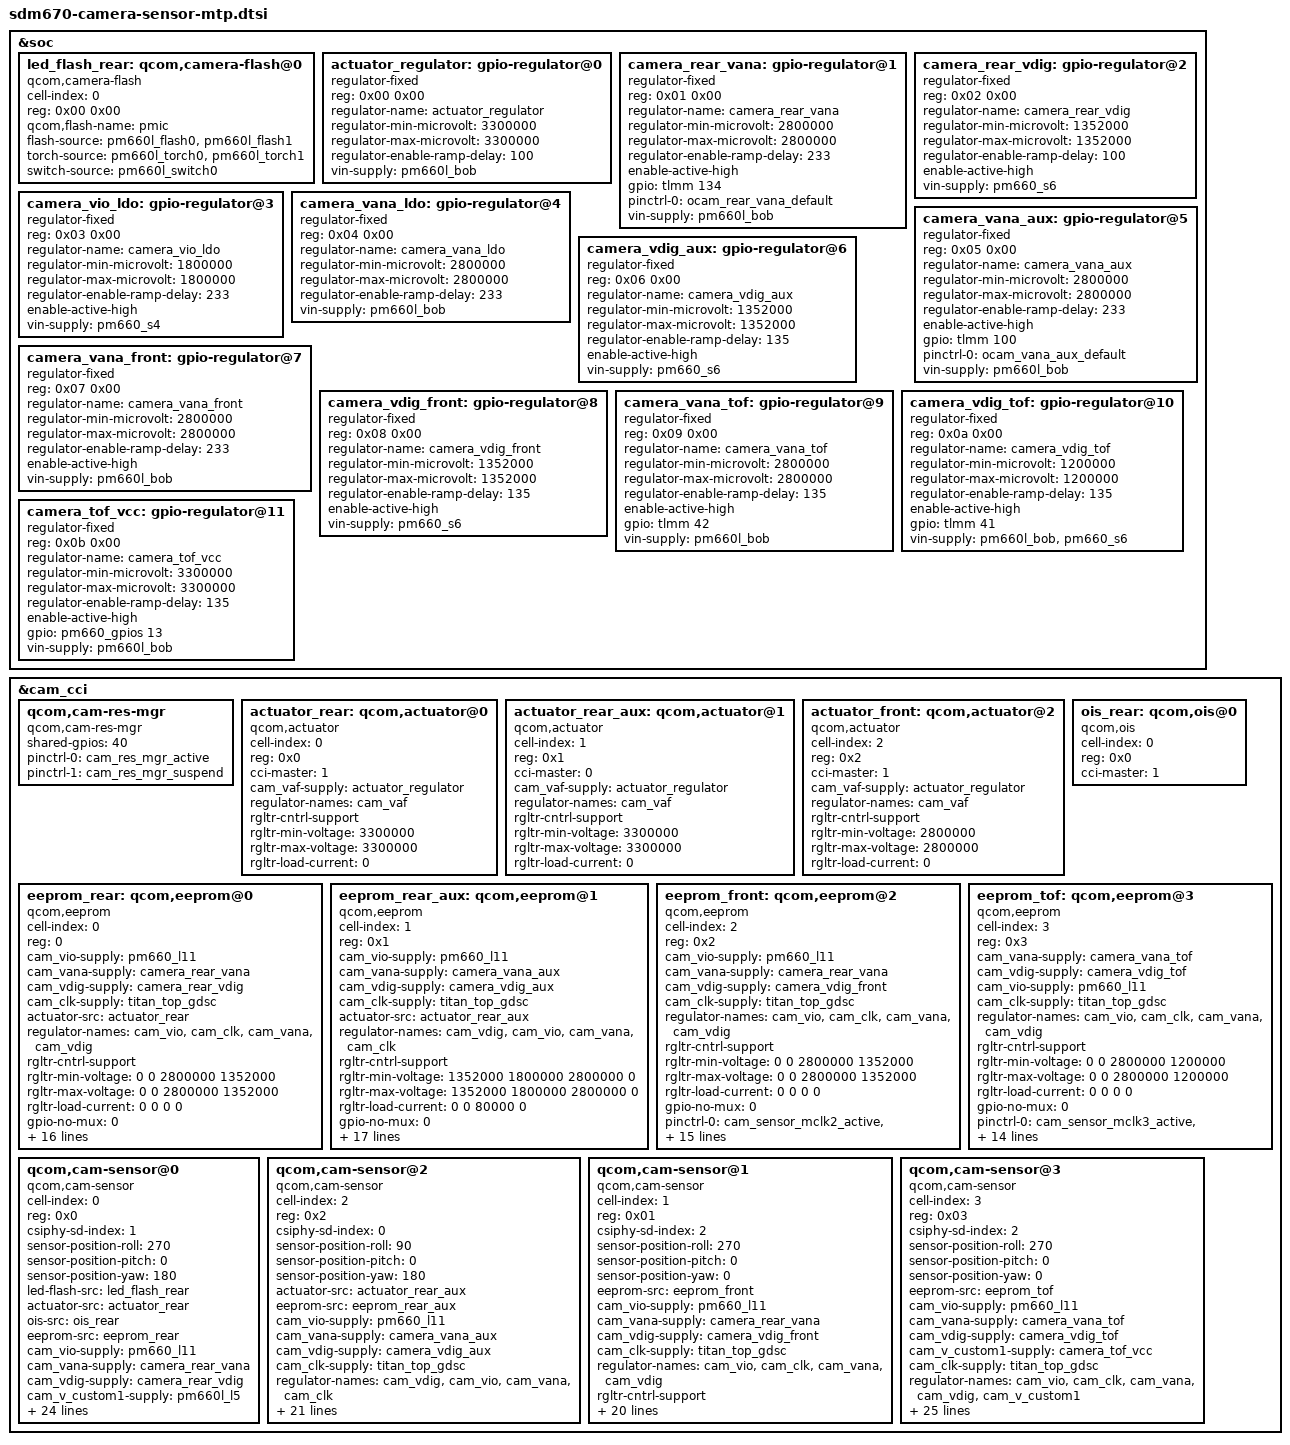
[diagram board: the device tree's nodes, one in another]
/*
 * Copyright (c) 2016-2018, The Linux Foundation. All rights reserved.
 *
 * This program is free software; you can redistribute it and/or modify
 * it under the terms of the GNU General Public License version 2 and
 * only version 2 as published by the Free Software Foundation.
 *
 * This program is distributed in the hope that it will be useful,
 * but WITHOUT ANY WARRANTY; without even the implied warranty of
 * MERCHANTABILITY or FITNESS FOR A PARTICULAR PURPOSE.  See the
 * GNU General Public License for more details.
 */

/*#ifndef VENDOR_EDIT*/
/*Yingpiao.Lin@Camera.Driver, 20180714, modify for oppo camera driver*/
/*
&soc {
	led_flash_rear: qcom,camera-flash@0 {
		cell-index = <0>;
		reg = <0x00 0x00>;
		compatible = "qcom,camera-flash";
		flash-source = <&pm660l_flash0 &pm660l_flash1>;
		torch-source = <&pm660l_torch0 &pm660l_torch1>;
		switch-source = <&pm660l_switch0>;
		status = "ok";
	};

	led_flash_rear_aux: qcom,camera-flash@1 {
		cell-index = <1>;
		reg = <0x01 0x00>;
		compatible = "qcom,camera-flash";
		flash-source = <&pm660l_flash0 &pm660l_flash1>;
		torch-source = <&pm660l_torch0 &pm660l_torch1>;
		switch-source = <&pm660l_switch0>;
		status = "ok";
	};

	led_flash_front: qcom,camera-flash@2 {
		cell-index = <2>;
		reg = <0x02 0x00>;
		compatible = "qcom,camera-flash";
		flash-source = <&pm660l_flash2>;
		torch-source = <&pm660l_torch2>;
		switch-source = <&pm660l_switch1>;
		status = "ok";
	};

	actuator_regulator: gpio-regulator@0 {
		compatible = "regulator-fixed";
		reg = <0x00 0x00>;
		regulator-name = "actuator_regulator";
		regulator-min-microvolt = <2800000>;
		regulator-max-microvolt = <2800000>;
		regulator-enable-ramp-delay = <100>;
		enable-active-high;
		gpio = <&tlmm 27 0>;
	};

	camera_ldo: gpio-regulator@2 {
		compatible = "regulator-fixed";
		reg = <0x02 0x00>;
		regulator-name = "camera_ldo";
		regulator-min-microvolt = <1352000>;
		regulator-max-microvolt = <1352000>;
		regulator-enable-ramp-delay = <233>;
		enable-active-high;
		gpio = <&pm660l_gpios 3 0>;
		pinctrl-names = "default";
		pinctrl-0 = <&camera_dvdd_en_default>;
		vin-supply = <&pm660_s6>;
	};

	camera_rear_ldo: gpio-regulator@1 {
		compatible = "regulator-fixed";
		reg = <0x01 0x00>;
		regulator-name = "camera_rear_ldo";
		regulator-min-microvolt = <1352000>;
		regulator-max-microvolt = <1352000>;
		regulator-enable-ramp-delay = <135>;
		enable-active-high;
		gpio = <&pm660l_gpios 4 0>;
		pinctrl-names = "default";
		pinctrl-0 = <&camera_rear_dvdd_en_default>;
		vin-supply = <&pm660_s6>;
	};

	camera_vio_ldo: gpio-regulator@3 {
		compatible = "regulator-fixed";
		reg = <0x03 0x00>;
		regulator-name = "camera_vio_ldo";
		regulator-min-microvolt = <1800000>;
		regulator-max-microvolt = <1800000>;
		regulator-enable-ramp-delay = <233>;
		enable-active-high;
		gpio = <&tlmm 29 0>;
		pinctrl-names = "default";
		pinctrl-0 = <&cam_sensor_rear_vio>;
		vin-supply = <&pm660_s4>;
	};

	camera_vana_ldo: gpio-regulator@4 {
		compatible = "regulator-fixed";
		reg = <0x04 0x00>;
		regulator-name = "camera_vana_ldo";
		regulator-min-microvolt = <2850000>;
		regulator-max-microvolt = <2850000>;
		regulator-enable-ramp-delay = <233>;
		enable-active-high;
		gpio = <&tlmm 8 0>;
		pinctrl-names = "default";
		pinctrl-0 = <&cam_sensor_rear_vana>;
		vin-supply = <&pm660l_bob>;
	};
};

&cam_cci {
	qcom,cam-res-mgr {
		compatible = "qcom,cam-res-mgr";
		status = "ok";
	};

	actuator_rear: qcom,actuator@0 {
		cell-index = <0>;
		reg = <0x0>;
		compatible = "qcom,actuator";
		cci-master = <0>;
		cam_vaf-supply = <&actuator_regulator>;
		regulator-names = "cam_vaf";
		rgltr-cntrl-support;
		rgltr-min-voltage = <2800000>;
		rgltr-max-voltage = <2800000>;
		rgltr-load-current = <0>;
	};

	actuator_rear_aux: qcom,actuator@1 {
		cell-index = <1>;
		reg = <0x1>;
		compatible = "qcom,actuator";
		cci-master = <1>;
		cam_vaf-supply = <&actuator_regulator>;
		regulator-names = "cam_vaf";
		rgltr-cntrl-support;
		rgltr-min-voltage = <2800000>;
		rgltr-max-voltage = <2800000>;
		rgltr-load-current = <0>;
	};

	actuator_front: qcom,actuator@2 {
		cell-index = <2>;
		reg = <0x2>;
		compatible = "qcom,actuator";
		cci-master = <1>;
		cam_vaf-supply = <&actuator_regulator>;
		regulator-names = "cam_vaf";
		rgltr-cntrl-support;
		rgltr-min-voltage = <2800000>;
		rgltr-max-voltage = <2800000>;
		rgltr-load-current = <0>;
	};

	ois_rear: qcom,ois@0 {
		cell-index = <0>;
		reg = <0x0>;
		compatible = "qcom,ois";
		cci-master = <0>;
		cam_vaf-supply = <&actuator_regulator>;
		regulator-names = "cam_vaf";
		rgltr-cntrl-support;
		rgltr-min-voltage = <2800000>;
		rgltr-max-voltage = <2800000>;
		rgltr-load-current = <0>;
		status = "disabled";
	};

	eeprom_rear: qcom,eeprom@0 {
		cell-index = <0>;
		reg = <0>;
		compatible = "qcom,eeprom";
		cam_vio-supply = <&camera_vio_ldo>;
		cam_vana-supply = <&camera_vana_ldo>;
		cam_vdig-supply = <&camera_rear_ldo>;
		cam_clk-supply = <&titan_top_gdsc>;
		cam_vaf-supply = <&actuator_regulator>;
		regulator-names = "cam_vio", "cam_vana", "cam_vdig",
			"cam_clk", "cam_vaf";
		rgltr-cntrl-support;
		rgltr-min-voltage = <1800000 2850000 1352000 0 2800000>;
		rgltr-max-voltage = <1800000 2850000 1352000 0 2800000>;
		rgltr-load-current = <0 80000 105000 0 0>;
		gpio-no-mux = <0>;
		pinctrl-names = "cam_default", "cam_suspend";
		pinctrl-0 = <&cam_sensor_mclk0_active
				&cam_sensor_rear_active>;
		pinctrl-1 = <&cam_sensor_mclk0_suspend
				&cam_sensor_rear_suspend>;
		gpios = <&tlmm 13 0>,
			<&tlmm 30 0>;
		gpio-reset = <1>;
		gpio-req-tbl-num = <0 1>;
		gpio-req-tbl-flags = <1 0>;
		gpio-req-tbl-label = "CAMIF_MCLK0",
					"CAM_RESET0";
		sensor-mode = <0>;
		cci-master = <0>;
		status = "ok";
		clocks = <&clock_camcc CAM_CC_MCLK0_CLK>;
		clock-names = "cam_clk";
		clock-cntl-level = "turbo";
		clock-rates = <24000000>;
	};

	eeprom_rear_aux: qcom,eeprom@1 {
		cell-index = <1>;
		reg = <0x1>;
		compatible = "qcom,eeprom";
		cam_vio-supply = <&camera_vio_ldo>;
		cam_vana-supply = <&camera_vana_ldo>;
		cam_vdig-supply = <&camera_ldo>;
		cam_clk-supply = <&titan_top_gdsc>;
		cam_vaf-supply = <&actuator_regulator>;
		regulator-names = "cam_vdig", "cam_vio", "cam_vana",
			"cam_clk", "cam_vaf";
		rgltr-cntrl-support;
		rgltr-min-voltage = <1352000 1800000 2850000 0 2800000>;
		rgltr-max-voltage = <1352000 1800000 2850000 0 2800000>;
		rgltr-load-current = <105000 0 80000 0 0>;
		gpio-no-mux = <0>;
		pinctrl-names = "cam_default", "cam_suspend";
		pinctrl-0 = <&cam_sensor_mclk1_active
				&cam_sensor_rear2_active>;
		pinctrl-1 = <&cam_sensor_mclk1_suspend
				&cam_sensor_rear2_suspend>;
		gpios = <&tlmm 14 0>,
			<&tlmm 28 0>;
		gpio-reset = <1>;
		gpio-req-tbl-num = <0 1>;
		gpio-req-tbl-flags = <1 0>;
		gpio-req-tbl-label = "CAMIF_MCLK1",
					"CAM_RESET1";
		sensor-position = <0>;
		sensor-mode = <0>;
		cci-master = <1>;
		status = "ok";
		clock-names = "cam_clk";
		clock-cntl-level = "turbo";
		clock-rates = <24000000>;
	};

	eeprom_front: qcom,eeprom@2 {
		cell-index = <2>;
		reg = <0x2>;
		compatible = "qcom,eeprom";
		cam_vio-supply = <&camera_vio_ldo>;
		cam_vana-supply = <&camera_vana_ldo>;
		cam_vdig-supply = <&camera_ldo>;
		cam_clk-supply = <&titan_top_gdsc>;
		cam_vaf-supply = <&actuator_regulator>;
		regulator-names = "cam_vio", "cam_vana", "cam_vdig",
			"cam_clk", "cam_vaf";
		rgltr-cntrl-support;
		rgltr-min-voltage = <1800000 2850000 1352000 0 2800000>;
		rgltr-max-voltage = <1800000 2850000 1352000 0 2800000>;
		rgltr-load-current = <0 80000 105000 0 0>;
		gpio-no-mux = <0>;
		pinctrl-names = "cam_default", "cam_suspend";
		pinctrl-0 = <&cam_sensor_mclk2_active
				 &cam_sensor_front_active>;
		pinctrl-1 = <&cam_sensor_mclk2_suspend
				 &cam_sensor_front_suspend>;
		gpios = <&tlmm 15 0>,
			<&tlmm 9 0>;
		gpio-reset = <1>;
		gpio-req-tbl-num = <0 1>;
		gpio-req-tbl-flags = <1 0>;
		gpio-req-tbl-label = "CAMIF_MCLK2",
					"CAM_RESET2";
		sensor-mode = <0>;
		cci-master = <1>;
		status = "ok";
		clocks = <&clock_camcc CAM_CC_MCLK2_CLK>;
		clock-names = "cam_clk";
		clock-cntl-level = "turbo";
		clock-rates = <24000000>;
	};

	qcom,cam-sensor@0 {
		cell-index = <0>;
		compatible = "qcom,cam-sensor";
		reg = <0x0>;
		csiphy-sd-index = <0>;
		sensor-position-roll = <270>;
		sensor-position-pitch = <0>;
		sensor-position-yaw = <180>;
		led-flash-src = <&led_flash_rear>;
		actuator-src = <&actuator_rear>;
		ois-src = <&ois_rear>;
		eeprom-src = <&eeprom_rear>;
		cam_vio-supply = <&camera_vio_ldo>;
		cam_vana-supply = <&camera_vana_ldo>;
		cam_vdig-supply = <&camera_rear_ldo>;
		cam_clk-supply = <&titan_top_gdsc>;
		regulator-names = "cam_vio", "cam_vana", "cam_vdig",
			"cam_clk";
		rgltr-cntrl-support;
		rgltr-min-voltage = <1800000 2850000 1352000 0>;
		rgltr-max-voltage = <1800000 2850000 1352000 0>;
		rgltr-load-current = <0 80000 105000 0>;
		gpio-no-mux = <0>;
		pinctrl-names = "cam_default", "cam_suspend";
		pinctrl-0 = <&cam_sensor_mclk0_active
				&cam_sensor_rear_active>;
		pinctrl-1 = <&cam_sensor_mclk0_suspend
				&cam_sensor_rear_suspend>;
		gpios = <&tlmm 13 0>,
			<&tlmm 30 0>;
		gpio-reset = <1>;
		gpio-req-tbl-num = <0 1>;
		gpio-req-tbl-flags = <1 0>;
		gpio-req-tbl-label = "CAMIF_MCLK0",
					"CAM_RESET0";
		sensor-mode = <0>;
		cci-master = <0>;
		status = "ok";
		clocks = <&clock_camcc CAM_CC_MCLK0_CLK>;
		clock-names = "cam_clk";
		clock-cntl-level = "turbo";
		clock-rates = <24000000>;
	};

	qcom,cam-sensor@1 {
		cell-index = <1>;
		compatible = "qcom,cam-sensor";
		reg = <0x1>;
		csiphy-sd-index = <1>;
		sensor-position-roll = <270>;
		sensor-position-pitch = <0>;
		sensor-position-yaw = <180>;
		led-flash-src = <&led_flash_rear_aux>;
		actuator-src = <&actuator_rear_aux>;
		eeprom-src = <&eeprom_rear_aux>;
		cam_vio-supply = <&camera_vio_ldo>;
		cam_vana-supply = <&camera_vana_ldo>;
		cam_vdig-supply = <&camera_ldo>;
		cam_clk-supply = <&titan_top_gdsc>;
		regulator-names = "cam_vdig", "cam_vio", "cam_vana",
			"cam_clk";
		rgltr-cntrl-support;
		rgltr-min-voltage = <1352000 1800000 2850000 0>;
		rgltr-max-voltage = <1352000 1800000 2850000 0>;
		rgltr-load-current = <105000 0 80000 0>;
		gpio-no-mux = <0>;
		pinctrl-names = "cam_default", "cam_suspend";
		pinctrl-0 = <&cam_sensor_mclk1_active
				&cam_sensor_rear2_active>;
		pinctrl-1 = <&cam_sensor_mclk1_suspend
				&cam_sensor_rear2_suspend>;
		gpios = <&tlmm 14 0>,
			<&tlmm 28 0>;
		gpio-reset = <1>;
		gpio-req-tbl-num = <0 1>;
		gpio-req-tbl-flags = <1 0>;
		gpio-req-tbl-label = "CAMIF_MCLK1",
					"CAM_RESET1";
		sensor-mode = <0>;
		cci-master = <1>;
		status = "ok";
		clocks = <&clock_camcc CAM_CC_MCLK1_CLK>;
		clock-names = "cam_clk";
		clock-cntl-level = "turbo";
		clock-rates = <24000000>;
	};

	qcom,cam-sensor@2 {
		cell-index = <2>;
		compatible = "qcom,cam-sensor";
		reg = <0x02>;
		csiphy-sd-index = <2>;
		sensor-position-roll = <270>;
		sensor-position-pitch = <0>;
		sensor-position-yaw = <0>;
		eeprom-src = <&eeprom_front>;
		actuator-src = <&actuator_front>;
		led-flash-src = <&led_flash_front>;
		cam_vio-supply = <&camera_vio_ldo>;
		cam_vana-supply = <&camera_vana_ldo>;
		cam_vdig-supply = <&camera_ldo>;
		cam_clk-supply = <&titan_top_gdsc>;
		regulator-names = "cam_vio", "cam_vana", "cam_vdig",
			"cam_clk";
		rgltr-cntrl-support;
		rgltr-min-voltage = <1800000 2850000 1352000 0>;
		rgltr-max-voltage = <1800000 2850000 1352000 0>;
		rgltr-load-current = <0 80000 105000 0>;
		gpio-no-mux = <0>;
		pinctrl-names = "cam_default", "cam_suspend";
		pinctrl-0 = <&cam_sensor_mclk2_active
				 &cam_sensor_front_active>;
		pinctrl-1 = <&cam_sensor_mclk2_suspend
				 &cam_sensor_front_suspend>;
		gpios = <&tlmm 15 0>,
			<&tlmm 9 0>;
		gpio-reset = <1>;
		gpio-req-tbl-num = <0 1>;
		gpio-req-tbl-flags = <1 0>;
		gpio-req-tbl-label = "CAMIF_MCLK2",
					"CAM_RESET2";
		sensor-mode = <0>;
		cci-master = <1>;
		status = "ok";
		clocks = <&clock_camcc CAM_CC_MCLK2_CLK>;
		clock-names = "cam_clk";
		clock-cntl-level = "turbo";
		clock-rates = <24000000>;
	};
};
*/
/*#else*/

&soc {
	led_flash_rear: qcom,camera-flash@0 {
		cell-index = <0>;
		reg = <0x00 0x00>;
		compatible = "qcom,camera-flash";
		qcom,flash-name = "pmic";
		flash-source = <&pm660l_flash0 &pm660l_flash1>;
		torch-source = <&pm660l_torch0 &pm660l_torch1>;
		switch-source = <&pm660l_switch0>;
		status = "ok";
	};

	/*led_flash_rear_aux: qcom,camera-flash@1 {
		cell-index = <1>;
		reg = <0x01 0x00>;
		compatible = "qcom,camera-flash";
		flash-source = <&pm660l_flash0 &pm660l_flash1>;
		torch-source = <&pm660l_torch0 &pm660l_torch1>;
		switch-source = <&pm660l_switch0>;
		status = "ok";
	};

	led_flash_front: qcom,camera-flash@2 {
		cell-index = <2>;
		reg = <0x02 0x00>;
		compatible = "qcom,camera-flash";
		flash-source = <&pm660l_flash2>;
		torch-source = <&pm660l_torch2>;
		switch-source = <&pm660l_switch1>;
		status = "ok";
	};*/

	actuator_regulator: gpio-regulator@0 {
		compatible = "regulator-fixed";
		reg = <0x00 0x00>;
		regulator-name = "actuator_regulator";
		regulator-min-microvolt = <3300000>;
		regulator-max-microvolt = <3300000>;
		regulator-enable-ramp-delay = <100>;
		vin-supply = <&pm660l_bob>;
	};

	camera_rear_vana: gpio-regulator@1 {
		compatible = "regulator-fixed";
		reg = <0x01 0x00>;
		regulator-name = "camera_rear_vana";
		regulator-min-microvolt = <2800000>;
		regulator-max-microvolt = <2800000>;
		regulator-enable-ramp-delay = <233>;
		enable-active-high;
		gpio = <&tlmm 134 0>;
		pinctrl-names = "default";
		pinctrl-0 = <&ocam_rear_vana_default>;
		vin-supply = <&pm660l_bob>;
	};

	camera_rear_vdig: gpio-regulator@2 {
		compatible = "regulator-fixed";
		reg = <0x02 0x00>;
		regulator-name = "camera_rear_vdig";
		regulator-min-microvolt = <1352000>;
		regulator-max-microvolt = <1352000>;
		regulator-enable-ramp-delay = <100>;
		enable-active-high;
		vin-supply = <&pm660_s6>;
	};

	camera_vio_ldo: gpio-regulator@3 {
		compatible = "regulator-fixed";
		reg = <0x03 0x00>;
		regulator-name = "camera_vio_ldo";
		regulator-min-microvolt = <1800000>;
		regulator-max-microvolt = <1800000>;
		regulator-enable-ramp-delay = <233>;
		enable-active-high;
		vin-supply = <&pm660_s4>;
	};

	camera_vana_ldo: gpio-regulator@4 {
		compatible = "regulator-fixed";
		reg = <0x04 0x00>;
		regulator-name = "camera_vana_ldo";
		regulator-min-microvolt = <2800000>;
		regulator-max-microvolt = <2800000>;
		regulator-enable-ramp-delay = <233>;
		vin-supply = <&pm660l_bob>;
	};

	camera_vana_aux: gpio-regulator@5 {
		compatible = "regulator-fixed";
		reg = <0x05 0x00>;
		regulator-name = "camera_vana_aux";
		regulator-min-microvolt = <2800000>;
		regulator-max-microvolt = <2800000>;
		regulator-enable-ramp-delay = <233>;
		enable-active-high;
		gpio = <&tlmm 100 0>;
		pinctrl-names = "default";
		pinctrl-0 = <&ocam_vana_aux_default>;
		vin-supply = <&pm660l_bob>;
	};

	camera_vdig_aux: gpio-regulator@6 {
		compatible = "regulator-fixed";
		reg = <0x06 0x00>;
		regulator-name = "camera_vdig_aux";
		regulator-min-microvolt = <1352000>;
		regulator-max-microvolt = <1352000>;
		regulator-enable-ramp-delay = <135>;
		enable-active-high;
		vin-supply = <&pm660_s6>;
	};

	camera_vana_front: gpio-regulator@7 {
		compatible = "regulator-fixed";
		reg = <0x07 0x00>;
		regulator-name = "camera_vana_front";
		regulator-min-microvolt = <2800000>;
		regulator-max-microvolt = <2800000>;
		regulator-enable-ramp-delay = <233>;
		enable-active-high;
		vin-supply = <&pm660l_bob>;
	};

	camera_vdig_front: gpio-regulator@8 {
		compatible = "regulator-fixed";
		reg = <0x08 0x00>;
		regulator-name = "camera_vdig_front";
		regulator-min-microvolt = <1352000>;
		regulator-max-microvolt = <1352000>;
		regulator-enable-ramp-delay = <135>;
		enable-active-high;
		vin-supply = <&pm660_s6>;
	};

	camera_vana_tof: gpio-regulator@9 {
		compatible = "regulator-fixed";
		reg = <0x09 0x00>;
		regulator-name = "camera_vana_tof";
		regulator-min-microvolt = <2800000>;
		regulator-max-microvolt = <2800000>;
		regulator-enable-ramp-delay = <135>;
		enable-active-high;
		gpio = <&tlmm 42 0>;
		vin-supply = <&pm660l_bob>;
	};

	camera_vdig_tof: gpio-regulator@10 {
		compatible = "regulator-fixed";
		reg = <0x0a 0x00>;
		regulator-name = "camera_vdig_tof";
		regulator-min-microvolt = <1200000>;
		regulator-max-microvolt = <1200000>;
		regulator-enable-ramp-delay = <135>;
		enable-active-high;
		gpio = <&tlmm 41 0>;
		vin-supply = <&pm660l_bob &pm660_s6>;
	};

	camera_tof_vcc: gpio-regulator@11 {
		compatible = "regulator-fixed";
		reg = <0x0b 0x00>;
		regulator-name = "camera_tof_vcc";
		regulator-min-microvolt = <3300000>;
		regulator-max-microvolt = <3300000>;
		regulator-enable-ramp-delay = <135>;
		enable-active-high;
		gpio = <&pm660_gpios 13 0>;
		vin-supply = <&pm660l_bob>;
	};
};

&cam_cci {
	qcom,cam-res-mgr {
		compatible = "qcom,cam-res-mgr";
		status = "ok";
		shared-gpios = <40>;
		pinctrl-names = "cam_res_mgr_default", "cam_res_mgr_suspend";
		pinctrl-0 = <&cam_res_mgr_active>;
		pinctrl-1 = <&cam_res_mgr_suspend>;
	};

	actuator_rear: qcom,actuator@0 {
		cell-index = <0>;
		reg = <0x0>;
		compatible = "qcom,actuator";
		cci-master = <1>;
		cam_vaf-supply = <&actuator_regulator>;
		regulator-names = "cam_vaf";
		rgltr-cntrl-support;
		rgltr-min-voltage = <3300000>;
		rgltr-max-voltage = <3300000>;
		rgltr-load-current = <0>;
	};

	actuator_rear_aux: qcom,actuator@1 {
		cell-index = <1>;
		reg = <0x1>;
		compatible = "qcom,actuator";
		cci-master = <0>;
		cam_vaf-supply = <&actuator_regulator>;
		regulator-names = "cam_vaf";
		rgltr-cntrl-support;
		rgltr-min-voltage = <3300000>;
		rgltr-max-voltage = <3300000>;
		rgltr-load-current = <0>;
	};

	actuator_front: qcom,actuator@2 {
		cell-index = <2>;
		reg = <0x2>;
		compatible = "qcom,actuator";
		cci-master = <1>;
		cam_vaf-supply = <&actuator_regulator>;
		regulator-names = "cam_vaf";
		rgltr-cntrl-support;
		rgltr-min-voltage = <2800000>;
		rgltr-max-voltage = <2800000>;
		rgltr-load-current = <0>;
	};

	ois_rear: qcom,ois@0 {
		cell-index = <0>;
		reg = <0x0>;
		compatible = "qcom,ois";
		cci-master = <1>;
		status = "ok";
	};

	eeprom_rear: qcom,eeprom@0 {
		cell-index = <0>;
		reg = <0>;
		compatible = "qcom,eeprom";
		cam_vio-supply = <&pm660_l11>;
		cam_vana-supply = <&camera_rear_vana>;
		cam_vdig-supply = <&camera_rear_vdig>;
		cam_clk-supply = <&titan_top_gdsc>;
		actuator-src = <&actuator_rear>;
		regulator-names = "cam_vio", "cam_clk", "cam_vana", "cam_vdig";
		rgltr-cntrl-support;
		rgltr-min-voltage = <0 0 2800000 1352000>;
		rgltr-max-voltage = <0 0 2800000 1352000>;
		rgltr-load-current = <0 0 0 0>;
		gpio-no-mux = <0>;
		pinctrl-names = "cam_default", "cam_suspend";
		pinctrl-0 = <&cam_sensor_mclk1_active
				&ocam_sensor_rear_active>;
		pinctrl-1 = <&cam_sensor_mclk1_suspend
				&ocam_sensor_rear_suspend>;
		gpios = <&tlmm 14 0>,
			<&tlmm 28 0>,
			<&tlmm 40 0>;
		gpio-reset = <1>;
		gpio-standby = <2>;
		gpio-req-tbl-num = <0 1 2>;
		gpio-req-tbl-flags = <1 0 0>;
		gpio-req-tbl-label = "CAMIF_MCLK0",
					"CAM_RESET0", "CAM_STBY0";
		sensor-mode = <0>;
		cci-master = <1>;
		status = "ok";
		clocks = <&clock_camcc CAM_CC_MCLK1_CLK>;
		clock-names = "cam_clk";
		clock-cntl-level = "turbo";
		clock-rates = <24000000>;
	};

	eeprom_rear_aux: qcom,eeprom@1 {
		cell-index = <1>;
		reg = <0x1>;
		compatible = "qcom,eeprom";
		cam_vio-supply = <&pm660_l11>;
		cam_vana-supply = <&camera_vana_aux>;
		cam_vdig-supply = <&camera_vdig_aux>;
		cam_clk-supply = <&titan_top_gdsc>;
		actuator-src = <&actuator_rear_aux>;
		regulator-names = "cam_vdig", "cam_vio", "cam_vana",
			"cam_clk";
		rgltr-cntrl-support;
		rgltr-min-voltage = <1352000 1800000 2800000 0>;
		rgltr-max-voltage = <1352000 1800000 2800000 0>;
		rgltr-load-current = <0 0 80000 0>;
		gpio-no-mux = <0>;
		pinctrl-names = "cam_default", "cam_suspend";
		pinctrl-0 = <&cam_sensor_mclk0_active
				&ocam_sensor_rear2_active>;
		pinctrl-1 = <&cam_sensor_mclk0_suspend
				&ocam_sensor_rear2_suspend>;
		gpios = <&tlmm 13 0>,
			<&tlmm 30 0>, <&tlmm 40 0>;
		gpio-reset = <1>;
		gpio-standby = <2>;
		gpio-req-tbl-num = <0 1 2>;
		gpio-req-tbl-flags = <1 0 0>;
		gpio-req-tbl-label = "CAMIF_MCLK1",
					"CAM_RESET1","CAM_STBY1";
		sensor-position = <0>;
		sensor-mode = <0>;
		cci-master = <0>;
		status = "ok";
		clocks = <&clock_camcc CAM_CC_MCLK0_CLK>;
		clock-names = "cam_clk";
		clock-cntl-level = "turbo";
		clock-rates = <24000000>;
	};

	eeprom_front: qcom,eeprom@2 {
		cell-index = <2>;
		reg = <0x2>;
		compatible = "qcom,eeprom";
		cam_vio-supply = <&pm660_l11>;
		cam_vana-supply = <&camera_rear_vana>;
		cam_vdig-supply = <&camera_vdig_front>;
		cam_clk-supply = <&titan_top_gdsc>;
		regulator-names = "cam_vio", "cam_clk", "cam_vana", "cam_vdig";
		rgltr-cntrl-support;
		rgltr-min-voltage = <0 0 2800000 1352000>;
		rgltr-max-voltage = <0 0 2800000 1352000>;
		rgltr-load-current = <0 0 0 0>;
		gpio-no-mux = <0>;
		pinctrl-names = "cam_default", "cam_suspend";
		pinctrl-0 = <&cam_sensor_mclk2_active
				&ocam_sensor_front_active>;
		pinctrl-1 = <&cam_sensor_mclk2_suspend
				&ocam_sensor_front_suspend>;
		gpios = <&tlmm 15 0>,
			<&tlmm 9 0>,
			<&tlmm 23 0>;
		gpio-reset = <1>;
		gpio-standby = <2>;
		gpio-req-tbl-num = <0 1 2>;
		gpio-req-tbl-flags = <1 0 0>;
		gpio-req-tbl-label = "CAMIF_MCLK2",
					"CAM_RESET2", "CAM_STBY";
		sensor-mode = <1>;
		cci-master = <1>;
		status = "ok";
		clocks = <&clock_camcc CAM_CC_MCLK2_CLK>;
		clock-names = "cam_clk";
		clock-cntl-level = "turbo";
		clock-rates = <24000000>;
	};

	eeprom_tof: qcom,eeprom@3 {
		cell-index = <3>;
		reg = <0x3>;
		compatible = "qcom,eeprom";
		cam_vana-supply = <&camera_vana_tof>;
		cam_vdig-supply = <&camera_vdig_tof>;
		cam_vio-supply = <&pm660_l11>;
		cam_clk-supply = <&titan_top_gdsc>;
		regulator-names = "cam_vio", "cam_clk", "cam_vana", "cam_vdig";
		rgltr-cntrl-support;
		rgltr-min-voltage = <0 0 2800000 1200000>;
		rgltr-max-voltage = <0 0 2800000 1200000>;
		rgltr-load-current = <0 0 0 0>;
		gpio-no-mux = <0>;
		pinctrl-names = "cam_default", "cam_suspend";
		pinctrl-0 = <&cam_sensor_mclk3_active
				 &cam_sensor_tof_active>;
		pinctrl-1 = <&cam_sensor_mclk3_suspend
				 &cam_sensor_tof_suspend>;
		gpios = <&tlmm 16 0>,
			<&tlmm 8 0>;
		gpio-reset = <1>;
		gpio-req-tbl-num = <0 1>;
		gpio-req-tbl-flags = <1 0>;
		gpio-req-tbl-label = "CAMIF_MCLK3",
					"CAM_RESET3";
		sensor-position = <1>;
		sensor-mode = <0>;
		cci-master = <0>;
		status = "ok";
		clocks = <&clock_camcc CAM_CC_MCLK3_CLK>;
		clock-names = "cam_clk";
		clock-cntl-level = "turbo";
		clock-rates = <24000000>;
	};

	qcom,cam-sensor@0 {
		cell-index = <0>;
		compatible = "qcom,cam-sensor";
		reg = <0x0>;
		csiphy-sd-index = <1>;
		sensor-position-roll = <270>;
		sensor-position-pitch = <0>;
		sensor-position-yaw = <180>;
		led-flash-src = <&led_flash_rear>;
		actuator-src = <&actuator_rear>;
		ois-src = <&ois_rear>;
		eeprom-src = <&eeprom_rear>;
		cam_vio-supply = <&pm660_l11>;
		cam_vana-supply = <&camera_rear_vana>;
		cam_vdig-supply = <&camera_rear_vdig>;
		cam_v_custom1-supply = <&pm660l_l5>;
		cam_clk-supply = <&titan_top_gdsc>;
		regulator-names = "cam_vio", "cam_clk", "cam_vana", "cam_vdig", "cam_v_custom1";
		rgltr-cntrl-support;
		rgltr-min-voltage = <0 0 2800000 1352000 2960000>;
		rgltr-max-voltage = <0 0 2800000 1352000 2960000>;
		rgltr-load-current = <0 0 0 0 800000>;
		gpio-no-mux = <0>;
		pinctrl-names = "cam_default", "cam_suspend";
		pinctrl-0 = <&cam_sensor_mclk1_active
				&ocam_sensor_rear_active>;
		pinctrl-1 = <&cam_sensor_mclk1_suspend
				&ocam_sensor_rear_suspend>;
		gpios = <&tlmm 14 0>,
			<&tlmm 28 0>,
			<&tlmm 40 0>;
		gpio-reset = <1>;
		gpio-standby = <2>;
		gpio-req-tbl-num = <0 1 2>;
		gpio-req-tbl-flags = <1 0 0>;
		gpio-req-tbl-label = "CAMIF_MCLK0",
					"CAM_RESET0", "CAM_STBY0";
		sensor-mode = <0>;
		cci-master = <1>;
		status = "ok";
		clocks = <&clock_camcc CAM_CC_MCLK1_CLK>;
		clock-names = "cam_clk";
		clock-cntl-level = "turbo";
		clock-rates = <24000000>;
	};

	qcom,cam-sensor@2 {
		cell-index = <2>;
		compatible = "qcom,cam-sensor";
		reg = <0x2>;
		csiphy-sd-index = <0>;
		sensor-position-roll = <90>;
		sensor-position-pitch = <0>;
		sensor-position-yaw = <180>;
		/*led-flash-src = <&led_flash_rear_aux>;*/
		actuator-src = <&actuator_rear_aux>;
		eeprom-src = <&eeprom_rear_aux>;
		cam_vio-supply = <&pm660_l11>;
		cam_vana-supply = <&camera_vana_aux>;
		cam_vdig-supply = <&camera_vdig_aux>;
		cam_clk-supply = <&titan_top_gdsc>;
		regulator-names = "cam_vdig", "cam_vio", "cam_vana",
			"cam_clk";
		rgltr-cntrl-support;
		rgltr-min-voltage = <1352000 1800000 2800000 0>;
		rgltr-max-voltage = <1352000 1800000 2800000 0>;
		rgltr-load-current = <0 0 80000 0>;
		gpio-no-mux = <0>;
		pinctrl-names = "cam_default", "cam_suspend";
		pinctrl-0 = <&cam_sensor_mclk0_active
				&ocam_sensor_rear2_active>;
		pinctrl-1 = <&cam_sensor_mclk0_suspend
				&ocam_sensor_rear2_suspend>;
		gpios = <&tlmm 13 0>,
			<&tlmm 30 0>, <&tlmm 40 0>;
		gpio-reset = <1>;
		gpio-standby = <2>;
		gpio-req-tbl-num = <0 1 2>;
		gpio-req-tbl-flags = <1 0 0>;
		gpio-req-tbl-label = "CAMIF_MCLK1",
					"CAM_RESET1","CAM_STBY1";
		sensor-mode = <0>;
		cci-master = <0>;
		status = "ok";
		clocks = <&clock_camcc CAM_CC_MCLK0_CLK>;
		clock-names = "cam_clk";
		clock-cntl-level = "turbo";
		clock-rates = <24000000>;
	};

	qcom,cam-sensor@1 {
		cell-index = <1>;
		compatible = "qcom,cam-sensor";
		reg = <0x01>;
		csiphy-sd-index = <2>;
		sensor-position-roll = <270>;
		sensor-position-pitch = <0>;
		sensor-position-yaw = <0>;
		eeprom-src = <&eeprom_front>;
		/*actuator-src = <&actuator_front>;*/
		/*led-flash-src = <&led_flash_front>;*/
		cam_vio-supply = <&pm660_l11>;
		cam_vana-supply = <&camera_rear_vana>;
		cam_vdig-supply = <&camera_vdig_front>;
		cam_clk-supply = <&titan_top_gdsc>;
		regulator-names = "cam_vio", "cam_clk", "cam_vana", "cam_vdig";
		rgltr-cntrl-support;
		rgltr-min-voltage = <0 0 2800000 1352000>;
		rgltr-max-voltage = <0 0 2800000 1352000>;
		rgltr-load-current = <0 0 0 0>;
		gpio-no-mux = <0>;
		pinctrl-names = "cam_default", "cam_suspend";
		pinctrl-0 = <&cam_sensor_mclk2_active
				&ocam_sensor_front_active>;
		pinctrl-1 = <&cam_sensor_mclk2_suspend
				&ocam_sensor_front_suspend>;
		gpios = <&tlmm 15 0>,
			<&tlmm 9 0>,
			<&tlmm 23 0>;
		gpio-reset = <1>;
		gpio-standby = <2>;
		gpio-req-tbl-num = <0 1 2>;
		gpio-req-tbl-flags = <1 0 0>;
		gpio-req-tbl-label = "CAMIF_MCLK2",
					"CAM_RESET2", "CAM_STBY";
		sensor-mode = <1>;
		cci-master = <1>;
		status = "ok";
		clocks = <&clock_camcc CAM_CC_MCLK2_CLK>;
		clock-names = "cam_clk";
		clock-cntl-level = "turbo";
		clock-rates = <24000000>;
	};

	qcom,cam-sensor@3 {
		cell-index = <3>;
		compatible = "qcom,cam-sensor";
		reg = <0x03>;
		csiphy-sd-index = <2>;
		sensor-position-roll = <270>;
		sensor-position-pitch = <0>;
		sensor-position-yaw = <0>;
		eeprom-src = <&eeprom_tof>;
		cam_vio-supply = <&pm660_l11>;
		cam_vana-supply = <&camera_vana_tof>;
		cam_vdig-supply = <&camera_vdig_tof>;
		cam_v_custom1-supply = <&camera_tof_vcc>;
		cam_clk-supply = <&titan_top_gdsc>;
		regulator-names = "cam_vio", "cam_clk", "cam_vana", "cam_vdig", "cam_v_custom1";
		rgltr-cntrl-support;
		rgltr-min-voltage = <0 0 2800000 1200000 3300000>;
		rgltr-max-voltage = <0 0 2800000 1200000 3300000>;
		rgltr-load-current = <0 0 0 0 0>;
		gpio-no-mux = <0>;
		pinctrl-names = "cam_default", "cam_suspend";
		pinctrl-0 = <&cam_sensor_mclk3_active
				&cam_sensor_tof_active
				&cam_tof_vcc_en>;
		pinctrl-1 = <&cam_sensor_mclk3_suspend
				&cam_sensor_tof_suspend
				&cam_tof_vcc_dis>;
		gpios = <&tlmm 16 0>,
			<&tlmm 8 0>,
			<&tlmm 43 0>,
			<&tlmm 23 0>,
			<&tlmm 27 0>;
		gpio-reset = <1>;
		gpio-custom1 = <2>;
		gpio-standby = <3>;
		gpio-custom2 = <4>;
		gpio-req-tbl-num = <0 1 2 3 4>;
		gpio-req-tbl-flags = <1 0 0 0 0>;
		gpio-req-tbl-label = "CAMIF_MCLK3",
					"CAM_RESET3",
					"TOF_WDEN",
					"CAM_STBY",
					"TOF_WDI";
		sensor-mode = <0>;
		cci-master = <0>;
		status = "ok";
		clocks = <&clock_camcc CAM_CC_MCLK3_CLK>;
		clock-names = "cam_clk";
		clock-cntl-level = "turbo";
		clock-rates = <24000000>;
		watchdog-gpio = <&tlmm 27 0x00>;
	};
};
/*#endif*/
